VERSION ""

NS_ :

BS_:

BU_:
	NEO
	MCU
	GTW
	EPAS
	DI
	ESP
	SBW
	STW
	APP
	DAS
	XXX

VAL_TABLE_ StW_AnglHP_Spd 16383 "SNA" ;
VAL_TABLE_ DI_aebFaultReason 15 "DI_AEB_FAULT_DAS_REQ_DI_UNAVAIL" 14 "DI_AEB_FAULT_ACCEL_REQ_INVALID" 13 "DI_AEB_FAULT_MIN_TIME_BTWN_EVENTS" 12 "DI_AEB_FAULT_ESP_MIA" 11 "DI_AEB_FAULT_ESP_FAULT" 10 "DI_AEB_FAULT_EPB_NOT_PARKED" 9 "DI_AEB_FAULT_ACCEL_OUT_OF_BOUNDS" 8 "DI_AEB_FAULT_PM_REQUEST" 7 "DI_AEB_FAULT_VEL_EST_ABNORMAL" 6 "DI_AEB_FAULT_DAS_SNA" 5 "DI_AEB_FAULT_DAS_CONTROL_MIA" 4 "DI_AEB_FAULT_SPEED_DELTA" 3 "DI_AEB_FAULT_EBR_FAULT" 2 "DI_AEB_FAULT_PM_MIA" 1 "DI_AEB_FAULT_EPB_MIA" 0 "DI_AEB_FAULT_NONE" ;
VAL_TABLE_ DI_aebLockState 3 "AEB_LOCK_STATE_SNA" 2 "AEB_LOCK_STATE_UNUSED" 1 "AEB_LOCK_STATE_UNLOCKED" 0 "AEB_LOCK_STATE_LOCKED" ;
VAL_TABLE_ DI_aebSmState 7 "DI_AEB_STATE_FAULT" 6 "DI_AEB_STATE_EXIT" 5 "DI_AEB_STATE_STANDSTILL" 4 "DI_AEB_STATE_STOPPING" 3 "DI_AEB_STATE_ENABLE" 2 "DI_AEB_STATE_ENABLE_INIT" 1 "DI_AEB_STATE_STANDBY" 0 "DI_AEB_STATE_UNAVAILABLE" ;
VAL_TABLE_ DI_aebState 7 "AEB_CAN_STATE_SNA" 4 "AEB_CAN_STATE_FAULT" 3 "AEB_CAN_STATE_STANDSTILL" 2 "AEB_CAN_STATE_ENABLED" 1 "AEB_CAN_STATE_STANDBY" 0 "AEB_CAN_STATE_UNAVAILABLE" ;
VAL_TABLE_ DI_epbInterfaceReady 1 "EPB_INTERFACE_READY" 0 "EPB_INTERFACE_NOT_READY" ;
VAL_TABLE_ DI_gear 7 "DI_GEAR_SNA" 4 "DI_GEAR_D" 3 "DI_GEAR_N" 2 "DI_GEAR_R" 1 "DI_GEAR_P" 0 "DI_GEAR_INVALID" ;
VAL_TABLE_ DI_gpoReason 8 "DI_GPO_NUMREASONS" 7 "DI_GPO_CAPACITOR_OVERTEMP" 6 "DI_GPO_NOT_ENOUGH_12V" 5 "DI_GPO_NO_BATTERY_POWER" 4 "DI_GPO_AMBIENT_OVERTEMP" 3 "DI_GPO_FLUID_DELTAT" 2 "DI_GPO_STATOR_OVERTEMP" 1 "DI_GPO_HEATSINK_OVERTEMP" 0 "DI_GPO_OUTLET_OVERTEMP" ;
VAL_TABLE_ DI_immobilizerCondition 1 "DI_IMM_CONDITION_LEARNED" 0 "DI_IMM_CONDITION_VIRGIN_SNA" ;
VAL_TABLE_ DI_immobilizerState 7 "DI_IMM_STATE_FAULT" 6 "DI_IMM_STATE_FAULTRETRY" 5 "DI_IMM_STATE_RESET" 4 "DI_IMM_STATE_LEARN" 3 "DI_IMM_STATE_DISARMED" 2 "DI_IMM_STATE_AUTHENTICATING" 1 "DI_IMM_STATE_REQUEST" 0 "DI_IMM_STATE_INIT_SNA" ;
VAL_TABLE_ DI_limpReason 24 "DI_LIMP_NUMREASONS" 23 "DI_LIMP_CAPACITOR_OVERTEMP" 22 "DI_LIMP_GTW_MIA" 21 "DI_LIMP_TRQCMD_VALIDITY_UNKNOWN" 20 "DI_LIMP_DI_MIA" 19 "DI_LIMP_CONFIG_MISMATCH" 18 "DI_LIMP_HEATSINK_TEMP" 17 "DI_LIMP_PMREQUEST" 16 "DI_LIMP_PMHEARTBEAT" 15 "DI_LIMP_TRQ_CROSS_CHECK" 14 "DI_LIMP_EXTERNAL_COMMAND" 13 "DI_LIMP_WRONG_CS_CALIBRATION" 12 "DI_LIMP_STATOR_TEMP" 11 "DI_LIMP_DELTAT_TOO_NEGATIVE" 10 "DI_LIMP_DELTAT_TOO_POSITIVE" 9 "DI_LIMP_AMBIENT_TEMP" 8 "DI_LIMP_OUTLET_TEMP" 7 "DI_LIMP_LOW_FLOW" 6 "DI_LIMP_BMS_MIA" 5 "DI_LIMP_12V_SUPPLY_UNDERVOLTAGE" 4 "DI_LIMP_NO_FLUID" 3 "DI_LIMP_NO_FUNC_HEATSINK_SENSOR" 2 "DI_LIMP_NO_FUNC_STATORT_SENSOR" 1 "DI_LIMP_BUSV_SENSOR_IRRATIONAL" 0 "DI_LIMP_PHASE_IMBALANCE" ;
VAL_TABLE_ DI_mode 2 "DI_MODE_DYNO" 1 "DI_MODE_DRIVE" 0 "DI_MODE_UNDEF" ;
VAL_TABLE_ DI_motorType 14 "DI_MOTOR_F2AE" 13 "DI_MOTOR_F2AD" 12 "DI_MOTOR_F2AC" 11 "DI_MOTOR_F2AB" 10 "DI_MOTOR_F1AC" 9 "DI_MOTOR_SSR1A" 8 "DI_MOTOR_F1A" 7 "DI_MOTOR_M7M6" 6 "DI_MOTOR_M8A" 5 "DI_MOTOR_M7M5" 4 "DI_MOTOR_M7M4" 3 "DI_MOTOR_M7M3" 2 "DI_MOTOR_ROADSTER_SPORT" 1 "DI_MOTOR_ROADSTER_BASE" 0 "DI_MOTOR_SNA" ;
VAL_TABLE_ DI_speedUnits 1 "DI_SPEED_KPH" 0 "DI_SPEED_MPH" ;
VAL_TABLE_ DI_state 4 "DI_STATE_ENABLE" 3 "DI_STATE_FAULT" 2 "DI_STATE_CLEAR_FAULT" 1 "DI_STATE_STANDBY" 0 "DI_STATE_PREAUTH" ;
VAL_TABLE_ DI_velocityEstimatorState 4 "VE_STATE_BACKUP_MOTOR" 3 "VE_STATE_BACKUP_WHEELS_B" 2 "VE_STATE_BACKUP_WHEELS_A" 1 "VE_STATE_WHEELS_NORMAL" 0 "VE_STATE_NOT_INITIALIZED" ;

BO_ 53 ACCELERATOR: 32 XXX
 SG_ CHECKSUM : 0|16@1+ (1,0) [0|65535] "" XXX
 SG_ COUNTER : 16|8@1+ (1,0) [0|255] "" XXX
 SG_ GEAR : 192|3@1+ (1,0) [0|7] "" XXX
 SG_ ACCELERATOR_PEDAL : 40|8@1+ (1,0) [0|255] "" XXX

BO_ 64 GEAR_ALT: 32 XXX
 SG_ CHECKSUM : 0|16@1+ (1,0) [0|65535] "" XXX
 SG_ COUNTER : 16|8@1+ (1,0) [0|255] "" XXX
 SG_ GEAR : 32|3@1+ (1,0) [0|7] "" XXX

BO_ 69 GEAR: 24 XXX
 SG_ CHECKSUM : 0|16@1+ (1,0) [0|65535] "" XXX
 SG_ COUNTER : 16|8@1+ (1,0) [0|255] "" XXX
 SG_ GEAR : 44|3@1+ (1,0) [0|7] "" XXX

BO_ 80 LKAS: 16 XXX
 SG_ STEER_REQ : 52|1@1+ (1,0) [0|1] "" XXX
 SG_ TORQUE_REQUEST : 41|11@1+ (1,-1024) [0|4095] "" XXX
 SG_ LKA_ICON : 38|2@1+ (1,0) [0|255] "" XXX
 SG_ NEW_SIGNAL_1 : 27|2@1+ (1,0) [0|255] "" XXX
 SG_ LFA_BUTTON : 56|1@1+ (1,0) [0|255] "" XXX
 SG_ COUNTER : 16|8@1+ (1,0) [0|255] "" XXX
 SG_ CHECKSUM : 0|16@1+ (1,0) [0|65535] "" XXX
 SG_ STEER_MODE : 65|3@1+ (1,0) [0|1] "" XXX
 SG_ LKA_WARNING : 32|1@1+ (1,0) [0|1] "" XXX
 SG_ LKA_ASSIST : 62|1@1+ (1,0) [0|1] "" XXX
 SG_ LKA_MODE : 24|3@1+ (1,0) [0|7] "" XXX
 SG_ NEW_SIGNAL_2 : 70|2@0+ (1,0) [0|3] "" XXX
 SG_ HAS_LANE_SAFETY : 80|1@0+ (1,0) [0|1] "" XXX
 SG_ NEW_SIGNAL_3 : 111|8@0+ (1,0) [0|255] "" XXX
 SG_ FCA_SYSWARN : 40|1@0+ (1,0) [0|1] "" XXX

BO_ 81 ADRV_0x51: 32 ADRV
 SG_ COUNTER : 16|8@1+ (1,0) [0|255] "" XXX
 SG_ CHECKSUM : 0|16@1+ (1,0) [0|65535] "" XXX

BO_ 96 ESP_STATUS: 32 XXX
 SG_ CHECKSUM : 0|16@1+ (1,0) [0|65535] "" XXX
 SG_ COUNTER : 16|8@1+ (1,0) [0|255] "" XXX
 SG_ TRACTION_AND_STABILITY_CONTROL : 42|3@1+ (1,0) [0|63] "" XXX
 SG_ BRAKE_PRESSURE : 128|10@1+ (1,0) [0|65535] "" XXX
 SG_ BRAKE_PRESSED : 148|1@1+ (1,0) [0|3] "" XXX

BO_ 101 BRAKE: 32 XXX
 SG_ CHECKSUM : 0|16@1+ (1,0) [0|65535] "" XXX
 SG_ COUNTER : 16|8@1+ (1,0) [0|255] "" XXX
 SG_ BRAKE_POSITION : 40|16@1- (1,0) [0|65535] "" XXX
 SG_ BRAKE_PRESSED : 57|1@1+ (1,0) [0|3] "" XXX

BO_ 112 GEAR_ALT_2: 32 XXX
 SG_ CHECKSUM : 0|16@1+ (1,0) [0|65535] "" XXX
 SG_ COUNTER : 16|8@1+ (1,0) [0|255] "" XXX
 SG_ GEAR : 60|3@1+ (1,0) [0|7] "" XXX

BO_ 160 WHEEL_SPEEDS: 24 XXX
 SG_ CHECKSUM : 0|16@1+ (1,0) [0|65535] "" XXX
 SG_ COUNTER : 16|8@1+ (1,0) [0|255] "" XXX
 SG_ MOVING_FORWARD : 56|1@0+ (1,0) [0|1] "" XXX
 SG_ MOVING_BACKWARD : 57|1@0+ (1,0) [0|1] "" XXX
 SG_ MOVING_FORWARD2 : 58|1@0+ (1,0) [0|1] "" XXX
 SG_ MOVING_BACKWARD2 : 59|1@0+ (1,0) [0|1] "" XXX
 SG_ WHEEL_SPEED_1 : 64|16@1+ (0.03125,0) [0|65535] "kph" XXX
 SG_ WHEEL_SPEED_2 : 80|16@1+ (0.03125,0) [0|65535] "kph" XXX
 SG_ WHEEL_SPEED_3 : 96|16@1+ (0.03125,0) [0|65535] "kph" XXX
 SG_ WHEEL_SPEED_4 : 112|16@1+ (0.03125,0) [0|65535] "kph" XXX

BO_ 234 MDPS: 24 XXX
 SG_ CHECKSUM : 0|16@1+ (1,0) [0|65535] "" XXX
 SG_ COUNTER : 16|8@1+ (1,0) [0|255] "" XXX
 SG_ LKA_ACTIVE : 48|1@0+ (1,0) [0|16777215] "" XXX
 SG_ LKA_FAULT : 54|1@0+ (1,0) [0|1] "" XXX
 SG_ STEERING_OUT_TORQUE : 64|12@1+ (0.1,-204.8) [0|65535] "" XXX
 SG_ STEERING_COL_TORQUE : 80|13@1+ (1,-4095) [0|4095] "" XXX
 SG_ STEERING_ANGLE : 96|16@1- (-0.1,0) [0|255] "deg" XXX
 SG_ STEERING_ANGLE_2 : 128|16@1- (-0.1,0) [0|65535] "deg" XXX

BO_ 256 ACCELERATOR_BRAKE_ALT: 32 XXX
 SG_ CHECKSUM : 0|16@1+ (1,0) [0|65535] "" XXX
 SG_ COUNTER : 16|8@1+ (1,0) [0|255] "" XXX
 SG_ BRAKE_PRESSED : 32|1@1+ (1,0) [0|1] "" XXX
 SG_ ACCELERATOR_PEDAL_PRESSED : 176|1@1+ (1,0) [0|1] "" XXX

BO_ 261 ACCELERATOR_ALT: 32 XXX
 SG_ CHECKSUM : 0|16@1+ (1,0) [0|65535] "" XXX
 SG_ COUNTER : 16|8@1+ (1,0) [0|255] "" XXX
 SG_ ACCELERATOR_PEDAL : 103|10@1+ (0.25,0) [0|1022] "" XXX

BO_ 272 LKAS_ALT: 32 XXX
 SG_ STEER_REQ : 52|1@1+ (1,0) [0|1] "" XXX
 SG_ TORQUE_REQUEST : 41|11@1+ (1,-1024) [0|4095] "" XXX
 SG_ LKA_ICON : 38|2@1+ (1,0) [0|255] "" XXX
 SG_ NEW_SIGNAL_1 : 27|2@1+ (1,0) [0|255] "" XXX
 SG_ LFA_BUTTON : 56|1@1+ (1,0) [0|255] "" XXX
 SG_ COUNTER : 16|8@1+ (1,0) [0|255] "" XXX
 SG_ CHECKSUM : 0|16@1+ (1,0) [0|65535] "" XXX
 SG_ STEER_MODE : 65|3@1+ (1,0) [0|1] "" XXX
 SG_ LKA_WARNING : 32|1@1+ (1,0) [0|1] "" XXX
 SG_ LKA_ASSIST : 62|1@1+ (1,0) [0|1] "" XXX
 SG_ LKA_MODE : 24|3@1+ (1,0) [0|7] "" XXX
 SG_ NEW_SIGNAL_2 : 70|2@0+ (1,0) [0|3] "" XXX
 SG_ HAS_LANE_SAFETY : 80|1@0+ (1,0) [0|1] "" XXX
 SG_ NEW_SIGNAL_3 : 111|8@0+ (1,0) [0|255] "" XXX
 SG_ FCA_SYSWARN : 40|1@0+ (1,0) [0|1] "" XXX

BO_ 293 STEERING_SENSORS: 16 XXX
 SG_ CHECKSUM : 0|16@1+ (1,0) [0|65535] "" XXX
 SG_ COUNTER : 16|8@1+ (1,0) [0|255] "" XXX
 SG_ STEERING_RATE : 40|8@1+ (4,0) [0|1016] "deg/s" XXX
 SG_ STEERING_ANGLE : 24|16@1- (-0.1,0) [0|255] "deg" XXX

BO_ 298 LFA: 16 ADRV
 SG_ STEER_REQ : 52|1@1+ (1,0) [0|1] "" XXX
 SG_ TORQUE_REQUEST : 41|11@1+ (1,-1024) [0|4095] "" XXX
 SG_ LKA_ICON : 38|2@1+ (1,0) [0|255] "" XXX
 SG_ NEW_SIGNAL_1 : 27|2@1+ (1,0) [0|255] "" XXX
 SG_ LFA_BUTTON : 56|1@1+ (1,0) [0|255] "" XXX
 SG_ COUNTER : 16|8@1+ (1,0) [0|255] "" XXX
 SG_ CHECKSUM : 0|16@1+ (1,0) [0|65535] "" XXX
 SG_ STEER_MODE : 65|3@1+ (1,0) [0|1] "" XXX
 SG_ LKA_WARNING : 32|1@1+ (1,0) [0|1] "" XXX
 SG_ LKA_ASSIST : 62|1@1+ (1,0) [0|1] "" XXX
 SG_ LKA_MODE : 24|3@1+ (1,0) [0|7] "" XXX
 SG_ NEW_SIGNAL_2 : 70|2@0+ (1,0) [0|3] "" XXX
 SG_ HAS_LANE_SAFETY : 80|1@0+ (1,0) [0|1] "" XXX
 SG_ NEW_SIGNAL_3 : 111|8@0+ (1,0) [0|255] "" XXX

BO_ 304 GEAR_SHIFTER: 16 XXX
 SG_ CHECKSUM : 0|16@1+ (1,0) [0|65535] "" XXX
 SG_ COUNTER : 16|8@1+ (1,0) [0|255] "" XXX
 SG_ PARK_BUTTON : 32|2@1+ (1,0) [0|3] "" XXX
 SG_ GEAR : 64|3@1+ (1,0) [0|7] "" XXX
 SG_ KNOB_POSITION : 40|3@1+ (1,0) [0|3] "" XXX

BO_ 357 SPAS1: 24 APRK
 SG_ CHECKSUM : 0|16@1+ (1,0) [0|65535] "" XXX
 SG_ COUNTER : 16|8@1+ (1,0) [0|0] "" XXX
 SG_ NEW_SIGNAL_1 : 96|16@1- (0.1,0) [0|0] "" XXX
 SG_ NEW_SIGNAL_2 : 90|3@1+ (1,0) [0|0] "" XXX

BO_ 362 SPAS2: 32 APRK
 SG_ CHECKSUM : 0|16@1+ (1,0) [0|65535] "" XXX
 SG_ COUNTER : 16|8@1+ (1,0) [0|0] "" XXX
 SG_ BLINKER_CONTROL : 133|3@1+ (1,0) [0|0] "" XXX

BO_ 373 TCS: 24 XXX
 SG_ CHECKSUM : 0|16@1+ (1,0) [0|65535] "" XXX
 SG_ COUNTER : 16|8@1+ (1,0) [0|255] "" XXX
 SG_ NEW_SIGNAL_1 : 80|1@0+ (1,0) [0|1] "" XXX
 SG_ NEW_SIGNAL_2 : 74|1@0+ (1,0) [0|1] "" XXX
 SG_ NEW_SIGNAL_3 : 76|1@0+ (1,0) [0|1] "" XXX
 SG_ NEW_SIGNAL_4 : 24|7@1+ (1,0) [0|127] "" XXX
 SG_ aBasis : 32|11@1+ (0.01,-10.23) [0|7] "m/s^2" XXX
 SG_ NEW_SIGNAL_5 : 72|1@0+ (1,0) [0|1] "" XXX
 SG_ NEW_SIGNAL_6 : 128|4@1+ (1,0) [0|15] "" XXX
 SG_ NEW_SIGNAL_7 : 135|2@0+ (1,0) [0|3] "" XXX
 SG_ PROBABLY_EQUIP : 136|2@1+ (1,0) [0|3] "" XXX
 SG_ AEB_EQUIP_MAYBE : 96|1@0+ (1,0) [0|1] "" XXX
 SG_ EQUIP_MAYBE : 64|1@0+ (1,0) [0|1] "" XXX
 SG_ DriverBraking : 81|1@0+ (1,0) [0|1] "" XXX
 SG_ DriverBrakingLowSens : 84|1@1+ (1,0) [0|1] "" XXX
 SG_ ACC_REQ : 68|1@0+ (1,0) [0|1] "" XXX
 SG_ ACCEL_REF_ACC : 48|11@1- (1,0) [0|1023] "" XXX
 SG_ ACCEnable : 67|2@0+ (1,0) [0|3] "" XXX

BO_ 352 ADRV_0x160: 16 ADRV
 SG_ CHECKSUM : 0|16@1+ (1,0) [0|65535] "" XXX
 SG_ COUNTER : 16|8@1+ (1,0) [0|255] "" XXX
 SG_ SET_ME_FF : 64|8@1+ (1,0) [0|255] "" XXX
 SG_ SET_ME_FC : 72|8@1+ (1,0) [0|255] "" XXX
 SG_ SET_ME_2 : 56|8@1+ (1,0) [0|1] "" XXX
 SG_ AEB_SETTING : 24|2@1+ (1,0) [0|255] "" XXX
 SG_ SET_ME_9 : 80|8@1+ (1,0) [0|255] "" XXX

BO_ 384 CAM_0x180: 32 CAMERA
 SG_ CHECKSUM : 0|16@1+ (1,0) [0|65535] "" XXX
 SG_ COUNTER : 16|8@1+ (1,0) [0|255] "" XXX

BO_ 385 CAM_0x181: 32 CAMERA
 SG_ CHECKSUM : 0|16@1+ (1,0) [0|65535] "" XXX
 SG_ COUNTER : 16|8@1+ (1,0) [0|255] "" XXX

BO_ 386 CAM_0x182: 32 CAMERA
 SG_ CHECKSUM : 0|16@1+ (1,0) [0|65535] "" XXX
 SG_ COUNTER : 16|8@1+ (1,0) [0|255] "" XXX

BO_ 387 CAM_0x183: 32 CAMERA
 SG_ CHECKSUM : 0|16@1+ (1,0) [0|65535] "" XXX
 SG_ COUNTER : 16|8@1+ (1,0) [0|255] "" XXX

BO_ 388 CAM_0x184: 32 CAMERA
 SG_ CHECKSUM : 0|16@1+ (1,0) [0|65535] "" XXX
 SG_ COUNTER : 16|8@1+ (1,0) [0|255] "" XXX

BO_ 389 CAM_0x185: 8 CAMERA
 SG_ CHECKSUM : 0|16@1+ (1,0) [0|65535] "" XXX
 SG_ COUNTER : 16|8@1+ (1,0) [0|255] "" XXX

BO_ 416 SCC_CONTROL: 32 ADRV
 SG_ CHECKSUM : 0|16@1+ (1,0) [0|65535] "" XXX
 SG_ NEW_SIGNAL_1 : 64|2@1+ (1,0) [0|3] "" XXX
 SG_ NEW_SIGNAL_8 : 170|4@1+ (1,0) [0|15] "" XXX
 SG_ ZEROS : 215|48@0+ (1,0) [0|281474976710655] "" XXX
 SG_ ZEROS_3 : 191|7@0+ (1,0) [0|127] "" XXX
 SG_ ZEROS_4 : 183|4@0+ (1,0) [0|63] "" XXX
 SG_ ZEROS_6 : 119|16@0+ (1,0) [0|65535] "" XXX
 SG_ ZEROS_8 : 95|5@0+ (1,0) [0|31] "" XXX
 SG_ NEW_SIGNAL_3 : 109|2@0+ (1,0) [0|1] "" XXX
 SG_ SET_ME_TMP_64 : 55|8@0+ (1,0) [0|63] "" XXX
 SG_ SET_ME_2 : 105|3@1+ (1,0) [0|7] "" XXX
 SG_ NEW_SIGNAL_6 : 104|1@0+ (1,0) [0|1] "" XXX
 SG_ COUNTER : 16|8@1+ (1,0) [0|255] "" XXX
 SG_ ZEROS_9 : 71|5@1+ (1,0) [0|15] "" XXX
 SG_ ZEROS_10 : 111|2@0+ (1,0) [0|3] "" XXX
 SG_ SET_ME_3 : 45|2@0+ (1,0) [0|3] "" XXX
 SG_ ObjValid : 46|1@0+ (1,0) [0|3] "" XXX
 SG_ NEW_SIGNAL_2 : 168|2@1+ (1,0) [0|3] "" XXX
 SG_ OBJ_STATUS : 176|3@1+ (1,0) [0|7] "" XXX
 SG_ ACC_ObjDist : 24|11@1+ (0.1,0) [0|204.7] "m" XXX
 SG_ ZEROS_5 : 77|11@1+ (1,0) [0|2047] "" XXX
 SG_ DISTANCE_SETTING : 88|3@1+ (1,0) [0|3] "" XXX
 SG_ ZEROS_2 : 207|5@0+ (1,0) [0|63] "" XXX
 SG_ CRUISE_STANDSTILL : 76|1@1+ (1,0) [0|1] "" XXX
 SG_ aReqRaw : 140|11@1+ (0.01,-10.23) [-10.23|10.24] "m/s^2" XXX
 SG_ aReqValue : 128|11@1+ (0.01,-10.23) [-10.23|10.24] "m/s^2" XXX
 SG_ ZEROS_7 : 63|8@0+ (1,0) [0|255] "" XXX
 SG_ ACCMode : 68|3@1+ (1,0) [0|7] "" XXX
 SG_ NEW_SIGNAL_12 : 35|9@1+ (0.1,0) [0|255] "" XXX
 SG_ JerkLowerLimit : 166|7@0+ (0.1,0) [0|12.7] "m/s^3" XXX
 SG_ StopReq : 184|1@0+ (1,0) [0|1] "" XXX
 SG_ NEW_SIGNAL_15 : 192|11@1+ (0.1,0) [0|204.7] "m" XXX
 SG_ VSetDis : 103|8@0+ (1,0) [0|255] "km/h or mph" XXX
 SG_ MainMode_ACC : 66|1@1+ (1,0) [0|1] "" XXX
 SG_ JerkUpperLimit : 158|7@0+ (0.1,0) [0|0] "" XXX

BO_ 426 CRUISE_BUTTONS_ALT: 16 XXX
 SG_ CHECKSUM : 0|16@1+ (1,0) [0|65535] "" XXX
 SG_ COUNTER : 16|8@1+ (1,0) [0|255] "" XXX
 SG_ NEW_SIGNAL_1 : 24|4@1+ (1,0) [0|15] "" XXX
 SG_ SET_ME_1 : 28|2@1+ (1,0) [0|3] "" XXX
 SG_ DISTANCE_UNIT : 30|1@1+ (1,0) [0|1] "" XXX
 SG_ NEW_SIGNAL_2 : 31|3@1+ (1,0) [0|7] "" XXX
 SG_ ADAPTIVE_CRUISE_MAIN_BTN : 34|1@1+ (1,0) [0|1] "" XXX
 SG_ NEW_SIGNAL_3 : 35|1@1+ (1,0) [0|1] "" XXX
 SG_ LFA_BTN : 39|1@1+ (1,0) [0|1] "" XXX
 SG_ CRUISE_BUTTONS : 36|3@1+ (1,0) [0|4] "" XXX
 SG_ NEW_SIGNAL_4 : 40|1@1+ (1,0) [0|1] "" XXX
 SG_ NORMAL_CRUISE_MAIN_BTN : 41|1@1+ (1,0) [0|1] "" XXX
 SG_ NEW_SIGNAL_5 : 42|2@1+ (1,0) [0|3] "" XXX
 SG_ SET_ME_2 : 44|3@1+ (1,0) [0|7] "" XXX
 SG_ NEW_SIGNAL_6 : 47|1@1+ (1,0) [0|1] "" XXX
 SG_ BYTE6 : 48|8@1+ (1,0) [0|255] "" XXX
 SG_ BYTE7 : 56|8@1+ (1,0) [0|255] "" XXX
 SG_ BYTE8 : 64|8@1+ (1,0) [0|255] "" XXX
 SG_ BYTE9 : 72|8@1+ (1,0) [0|255] "" XXX
 SG_ BYTE10 : 80|8@1+ (1,0) [0|255] "" XXX
 SG_ BYTE11 : 88|8@1+ (1,0) [0|255] "" XXX
 SG_ BYTE12 : 96|8@1+ (1,0) [0|255] "" XXX
 SG_ BYTE13 : 104|8@1+ (1,0) [0|255] "" XXX
 SG_ BYTE14 : 112|8@1+ (1,0) [0|255] "" XXX
 SG_ BYTE15 : 120|8@1+ (1,0) [0|255] "" XXX

BO_ 438 CAM_0x1b6: 32 CAMERA
 SG_ CHECKSUM : 0|16@1+ (1,0) [0|65535] "" XXX
 SG_ COUNTER : 16|8@1+ (1,0) [0|255] "" XXX

BO_ 439 CAM_0x1b7: 32 CAMERA
 SG_ CHECKSUM : 0|16@1+ (1,0) [0|65535] "" XXX
 SG_ COUNTER : 16|8@1+ (1,0) [0|255] "" XXX

BO_ 440 CAM_0x1b8: 32 CAMERA
 SG_ CHECKSUM : 0|16@1+ (1,0) [0|65535] "" XXX
 SG_ COUNTER : 16|8@1+ (1,0) [0|255] "" XXX

BO_ 441 CAM_0x1b9: 32 CAMERA
 SG_ CHECKSUM : 0|16@1+ (1,0) [0|65535] "" XXX
 SG_ COUNTER : 16|8@1+ (1,0) [0|255] "" XXX

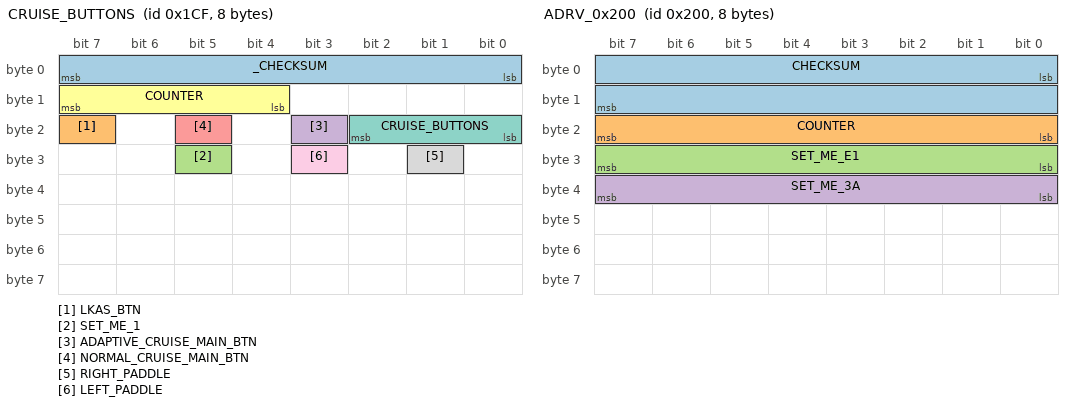
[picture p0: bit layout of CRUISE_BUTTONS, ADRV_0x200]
BO_ 463 CRUISE_BUTTONS: 8 XXX
 SG_ _CHECKSUM : 0|8@1+ (1,0) [0|65535] "" XXX
 SG_ LKAS_BTN : 23|1@1+ (1,0) [0|1] "" XXX
 SG_ SET_ME_1 : 29|1@1+ (1,0) [0|1] "" XXX
 SG_ ADAPTIVE_CRUISE_MAIN_BTN : 19|1@1+ (1,0) [0|1] "" XXX
 SG_ NORMAL_CRUISE_MAIN_BTN : 21|1@1+ (1,0) [0|1] "" XXX
 SG_ COUNTER : 12|4@1+ (1,0) [0|255] "" XXX
 SG_ CRUISE_BUTTONS : 16|3@1+ (1,0) [0|3] "" XXX
 SG_ RIGHT_PADDLE : 25|1@1+ (1,0) [0|1] "" XXX
 SG_ LEFT_PADDLE : 27|1@1+ (1,0) [0|1] "" XXX

BO_ 474 ADRV_0x1da: 32 ADRV
 SG_ CHECKSUM : 0|16@1+ (1,0) [0|65535] "" XXX
 SG_ COUNTER : 16|8@1+ (1,0) [0|255] "" XXX
 SG_ SET_ME_22 : 31|8@0+ (1,0) [0|255] "" XXX
 SG_ SET_ME_41 : 47|8@0+ (1,0) [0|255] "" XXX

BO_ 480 LFAHDA_CLUSTER: 16 ADRV
 SG_ CHECKSUM : 0|16@1+ (1,0) [0|65535] "" XXX
 SG_ COUNTER : 16|8@1+ (1,0) [0|255] "" XXX
 SG_ HDA_ICON : 31|1@1+ (1,0) [0|1] "" XXX
 SG_ LFA_ICON : 47|2@1+ (1,0) [0|3] "" XXX
 SG_ NEW_SIGNAL_1 : 32|3@1+ (1,0) [0|7] "" XXX
 SG_ NEW_SIGNAL_2 : 30|1@0+ (1,0) [0|1] "" XXX
 SG_ NEW_SIGNAL_3 : 49|1@0+ (1,0) [0|1] "" XXX
 SG_ NEW_SIGNAL_4 : 24|1@0+ (1,0) [0|1] "" XXX

BO_ 490 ADRV_0x1ea: 32 ADRV
 SG_ CHECKSUM : 0|16@1+ (1,0) [0|65535] "" XXX
 SG_ COUNTER : 16|8@1+ (1,0) [0|255] "" XXX
 SG_ SET_ME_1C : 31|8@0+ (1,0) [0|255] "" XXX
 SG_ NEW_SIGNAL_1 : 32|2@1+ (1,0) [0|3] "" XXX
 SG_ NEW_SIGNAL_2 : 47|2@0+ (1,0) [0|3] "" XXX
 SG_ NEW_SIGNAL_3 : 55|8@0+ (1,0) [0|255] "" XXX
 SG_ NEW_SIGNAL_4 : 64|6@1+ (1,0) [0|31] "" XXX
 SG_ NEW_SIGNAL_5 : 72|2@1+ (1,0) [0|3] "" XXX
 SG_ NEW_SIGNAL_6 : 75|5@1+ (1,0) [0|31] "" XXX
 SG_ NEW_SIGNAL_7 : 80|5@1+ (1,0) [0|31] "" XXX
 SG_ NEW_SIGNAL_8 : 88|7@1+ (1,0) [0|127] "" XXX
 SG_ NEW_SIGNAL_9 : 96|1@0+ (1,0) [0|1] "" XXX
 SG_ NEW_SIGNAL_10 : 143|5@0+ (1,0) [0|31] "" XXX
 SG_ NEW_SIGNAL_11 : 144|3@1+ (1,0) [0|7] "" XXX
 SG_ NEW_SIGNAL_12 : 152|6@1+ (1,0) [0|63] "" XXX
 SG_ NEW_SIGNAL_13 : 160|1@0+ (1,0) [0|1] "" XXX
 SG_ NEW_SIGNAL_14 : 163|5@1+ (1,0) [0|31] "" XXX
 SG_ NEW_SIGNAL_15 : 175|4@0+ (1,0) [0|63] "" XXX
 SG_ NEW_SIGNAL_16 : 168|3@1+ (1,0) [0|7] "" XXX
 SG_ NEW_SIGNAL_17 : 176|2@1+ (1,0) [0|3] "" XXX
 SG_ NEW_SIGNAL_18 : 184|1@0+ (1,0) [0|1] "" XXX
 SG_ NEW_SIGNAL_19 : 208|3@1+ (1,0) [0|7] "" XXX
 SG_ NEW_SIGNAL_20 : 212|1@0+ (1,0) [0|1] "" XXX
 SG_ SET_ME_FF : 120|8@1+ (1,0) [0|255] "" XXX
 SG_ SET_ME_TMP_F : 232|5@1+ (1,0) [0|31] "" XXX
 SG_ SET_ME_TMP_F_2 : 240|5@1+ (1,0) [0|31] "" XXX

BO_ 507 CAM_0x1fb: 32 CAMERA
 SG_ CHECKSUM : 0|16@1+ (1,0) [0|65535] "" XXX
 SG_ COUNTER : 16|8@1+ (1,0) [0|255] "" XXX

BO_ 512 ADRV_0x200: 8 ADRV
 SG_ CHECKSUM : 0|16@1+ (1,0) [0|65535] "" XXX
 SG_ COUNTER : 16|8@1+ (1,0) [0|255] "" XXX
 SG_ SET_ME_E1 : 24|8@1+ (1,0) [0|255] "" XXX
 SG_ SET_ME_3A : 32|8@1+ (1,0) [0|255] "" XXX

BO_ 513 RADAR_0x201: 32 FRONT_RADAR
 SG_ CHECKSUM : 0|16@1+ (1,0) [0|65535] "" XXX
 SG_ COUNTER : 16|8@1+ (1,0) [0|255] "" XXX

BO_ 528 RADAR_0x210: 32 FRONT_RADAR
 SG_ CHECKSUM : 0|16@1+ (1,0) [0|65535] "" XXX
 SG_ COUNTER : 16|8@1+ (1,0) [0|255] "" XXX

BO_ 529 RADAR_0x211: 32 FRONT_RADAR
 SG_ CHECKSUM : 0|16@1+ (1,0) [0|65535] "" XXX
 SG_ COUNTER : 16|8@1+ (1,0) [0|255] "" XXX

BO_ 530 RADAR_0x212: 32 FRONT_RADAR
 SG_ CHECKSUM : 0|16@1+ (1,0) [0|65535] "" XXX
 SG_ COUNTER : 16|8@1+ (1,0) [0|255] "" XXX

BO_ 531 RADAR_0x213: 32 FRONT_RADAR
 SG_ CHECKSUM : 0|16@1+ (1,0) [0|65535] "" XXX
 SG_ COUNTER : 16|8@1+ (1,0) [0|255] "" XXX

BO_ 532 RADAR_0x214: 32 FRONT_RADAR
 SG_ CHECKSUM : 0|16@1+ (1,0) [0|65535] "" XXX
 SG_ COUNTER : 16|8@1+ (1,0) [0|255] "" XXX

BO_ 533 RADAR_0x215: 32 FRONT_RADAR
 SG_ CHECKSUM : 0|16@1+ (1,0) [0|65535] "" XXX
 SG_ COUNTER : 16|8@1+ (1,0) [0|255] "" XXX

BO_ 534 RADAR_0x216: 32 FRONT_RADAR
 SG_ CHECKSUM : 0|16@1+ (1,0) [0|65535] "" XXX
 SG_ COUNTER : 16|8@1+ (1,0) [0|255] "" XXX

BO_ 535 RADAR_0x217: 32 FRONT_RADAR
 SG_ CHECKSUM : 0|16@1+ (1,0) [0|65535] "" XXX
 SG_ COUNTER : 16|8@1+ (1,0) [0|255] "" XXX

BO_ 536 RADAR_0x218: 32 FRONT_RADAR
 SG_ CHECKSUM : 0|16@1+ (1,0) [0|65535] "" XXX
 SG_ COUNTER : 16|8@1+ (1,0) [0|255] "" XXX

BO_ 537 RADAR_0x219: 32 FRONT_RADAR
 SG_ CHECKSUM : 0|16@1+ (1,0) [0|65535] "" XXX
 SG_ COUNTER : 16|8@1+ (1,0) [0|255] "" XXX

BO_ 538 RADAR_0x21a: 32 FRONT_RADAR
 SG_ CHECKSUM : 0|16@1+ (1,0) [0|65535] "" XXX
 SG_ COUNTER : 16|8@1+ (1,0) [0|255] "" XXX

BO_ 539 RADAR_0x21b: 32 FRONT_RADAR
 SG_ CHECKSUM : 0|16@1+ (1,0) [0|65535] "" XXX
 SG_ COUNTER : 16|8@1+ (1,0) [0|255] "" XXX

BO_ 540 RADAR_0x21c: 32 FRONT_RADAR
 SG_ CHECKSUM : 0|16@1+ (1,0) [0|65535] "" XXX
 SG_ COUNTER : 16|8@1+ (1,0) [0|255] "" XXX

BO_ 541 RADAR_0x21d: 32 FRONT_RADAR
 SG_ CHECKSUM : 0|16@1+ (1,0) [0|65535] "" XXX
 SG_ COUNTER : 16|8@1+ (1,0) [0|255] "" XXX

BO_ 542 RADAR_0x21e: 32 FRONT_RADAR
 SG_ CHECKSUM : 0|16@1+ (1,0) [0|65535] "" XXX
 SG_ COUNTER : 16|8@1+ (1,0) [0|255] "" XXX

BO_ 543 RADAR_0x21f: 32 FRONT_RADAR
 SG_ CHECKSUM : 0|16@1+ (1,0) [0|65535] "" XXX
 SG_ COUNTER : 16|8@1+ (1,0) [0|255] "" XXX

BO_ 576 RADAR_0x240: 16 FRONT_RADAR
 SG_ CHECKSUM : 0|16@1+ (1,0) [0|65535] "" XXX
 SG_ COUNTER : 16|8@1+ (1,0) [0|255] "" XXX

BO_ 593 RADAR_0x251: 16 FRONT_RADAR
 SG_ CHECKSUM : 0|16@1+ (1,0) [0|65535] "" XXX
 SG_ COUNTER : 16|8@1+ (1,0) [0|255] "" XXX

BO_ 674 CAM_0x2a2: 32 CAMERA
 SG_ CHECKSUM : 0|16@1+ (1,0) [0|65535] "" XXX
 SG_ COUNTER : 16|8@1+ (1,0) [0|255] "" XXX

BO_ 675 CAM_0x2a3: 32 CAMERA
 SG_ CHECKSUM : 0|16@1+ (1,0) [0|65535] "" XXX
 SG_ COUNTER : 16|8@1+ (1,0) [0|255] "" XXX

BO_ 676 CAM_0x2a4: 24 XXX
 SG_ CHECKSUM : 0|16@1+ (1,0) [0|65535] "" XXX
 SG_ COUNTER : 16|8@1+ (1,0) [0|255] "" XXX
 SG_ BYTE3 : 24|8@1+ (1,0) [0|255] "" XXX
 SG_ BYTE4 : 32|8@1+ (1,0) [0|255] "" XXX
 SG_ BYTE5 : 40|8@1+ (1,0) [0|255] "" XXX
 SG_ BYTE6 : 48|8@1+ (1,0) [0|255] "" XXX
 SG_ LEFT_LANE_LINE : 56|2@1+ (1,0) [0|3] "" XXX
 SG_ SET_ME_0 : 58|2@1+ (1,0) [0|3] "" XXX
 SG_ RIGHT_LANE_LINE : 60|2@1+ (1,0) [0|3] "" XXX
 SG_ SET_ME_0_2 : 62|2@1+ (1,0) [0|3] "" XXX
 SG_ BYTE8 : 64|8@1+ (1,0) [0|255] "" XXX
 SG_ BYTE9 : 72|8@1+ (1,0) [0|255] "" XXX
 SG_ BYTE10 : 80|8@1+ (1,0) [0|255] "" XXX
 SG_ BYTE11 : 88|8@1+ (1,0) [0|255] "" XXX
 SG_ BYTE12 : 96|8@1+ (1,0) [0|255] "" XXX
 SG_ BYTE13 : 104|8@1+ (1,0) [0|255] "" XXX
 SG_ BYTE14 : 112|8@1+ (1,0) [0|255] "" XXX
 SG_ BYTE15 : 120|8@1+ (1,0) [0|255] "" XXX
 SG_ BYTE16 : 128|8@1+ (1,0) [0|255] "" XXX
 SG_ BYTE17 : 136|8@1+ (1,0) [0|255] "" XXX
 SG_ BYTE18 : 144|8@1+ (1,0) [0|255] "" XXX
 SG_ BYTE19 : 152|8@1+ (1,0) [0|255] "" XXX
 SG_ BYTE20 : 160|8@1+ (1,0) [0|255] "" XXX
 SG_ BYTE21 : 168|8@1+ (1,0) [0|255] "" XXX
 SG_ BYTE22 : 176|8@1+ (1,0) [0|255] "" XXX
 SG_ BYTE23 : 184|8@1+ (1,0) [0|255] "" XXX

BO_ 699 CAM_0x2bb: 32 CAMERA
 SG_ CHECKSUM : 0|16@1+ (1,0) [0|65535] "" XXX
 SG_ COUNTER : 16|8@1+ (1,0) [0|255] "" XXX

BO_ 700 CAM_0x2bc: 32 CAMERA
 SG_ CHECKSUM : 0|16@1+ (1,0) [0|65535] "" XXX
 SG_ COUNTER : 16|8@1+ (1,0) [0|255] "" XXX

BO_ 701 CAM_0x2bd: 32 CAMERA
 SG_ CHECKSUM : 0|16@1+ (1,0) [0|65535] "" XXX
 SG_ COUNTER : 16|8@1+ (1,0) [0|255] "" XXX

BO_ 702 CAM_0x2be: 32 CAMERA
 SG_ CHECKSUM : 0|16@1+ (1,0) [0|65535] "" XXX
 SG_ COUNTER : 16|8@1+ (1,0) [0|255] "" XXX

BO_ 736 MANUAL_SPEED_LIMIT_ASSIST: 32 XXX
 SG_ CHECKSUM : 0|16@1+ (1,0) [0|65535] "" XXX
 SG_ COUNTER : 16|8@1+ (1,0) [0|255] "" XXX
 SG_ MSLA_STATUS : 26|2@1+ (1,0) [0|3] "" XXX
 SG_ MSLA_ENABLED : 38|1@1+ (1,0) [0|1] "" XXX
 SG_ MAX_SPEED : 55|8@0+ (1,0) [0|255] "" XXX
 SG_ MAX_SPEED_COPY : 144|8@1+ (1,0) [0|255] "" XXX

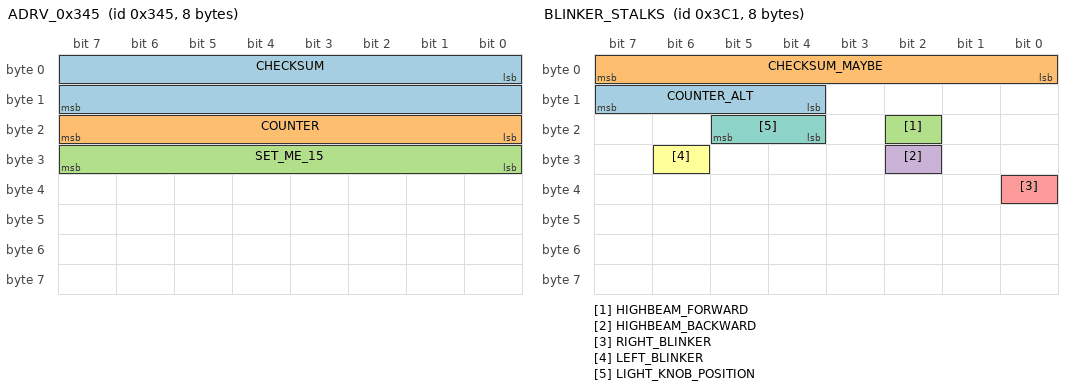
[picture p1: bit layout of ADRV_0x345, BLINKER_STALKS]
BO_ 837 ADRV_0x345: 8 ADRV
 SG_ CHECKSUM : 0|16@1+ (1,0) [0|65535] "" XXX
 SG_ COUNTER : 16|8@1+ (1,0) [0|255] "" XXX
 SG_ SET_ME_15 : 24|8@1+ (1,0) [0|255] "" XXX

BO_ 866 CAM_0x362: 32 CAMERA
 SG_ CHECKSUM : 0|16@1+ (1,0) [0|65535] "" XXX
 SG_ COUNTER : 16|8@1+ (1,0) [0|255] "" XXX
 SG_ BYTE3 : 24|8@1+ (1,0) [0|255] "" XXX
 SG_ BYTE4 : 32|8@1+ (1,0) [0|255] "" XXX
 SG_ BYTE5 : 40|8@1+ (1,0) [0|255] "" XXX
 SG_ BYTE6 : 48|8@1+ (1,0) [0|255] "" XXX
 SG_ LEFT_LANE_LINE : 56|2@1+ (1,0) [0|3] "" XXX
 SG_ SET_ME_0 : 58|2@1+ (1,0) [0|3] "" XXX
 SG_ RIGHT_LANE_LINE : 60|2@1+ (1,0) [0|3] "" XXX
 SG_ SET_ME_0_2 : 62|2@1+ (1,0) [0|3] "" XXX
 SG_ BYTE8 : 64|8@1+ (1,0) [0|255] "" XXX
 SG_ BYTE9 : 72|8@1+ (1,0) [0|255] "" XXX
 SG_ BYTE10 : 80|8@1+ (1,0) [0|255] "" XXX
 SG_ BYTE11 : 88|8@1+ (1,0) [0|255] "" XXX
 SG_ BYTE12 : 96|8@1+ (1,0) [0|255] "" XXX
 SG_ BYTE13 : 104|8@1+ (1,0) [0|255] "" XXX
 SG_ BYTE14 : 112|8@1+ (1,0) [0|255] "" XXX
 SG_ BYTE15 : 120|8@1+ (1,0) [0|255] "" XXX
 SG_ BYTE16 : 128|8@1+ (1,0) [0|255] "" XXX
 SG_ BYTE17 : 136|8@1+ (1,0) [0|255] "" XXX
 SG_ BYTE18 : 144|8@1+ (1,0) [0|255] "" XXX
 SG_ BYTE19 : 152|8@1+ (1,0) [0|255] "" XXX
 SG_ BYTE20 : 160|8@1+ (1,0) [0|255] "" XXX
 SG_ BYTE21 : 168|8@1+ (1,0) [0|255] "" XXX
 SG_ BYTE22 : 176|8@1+ (1,0) [0|255] "" XXX
 SG_ BYTE23 : 184|8@1+ (1,0) [0|255] "" XXX
 SG_ BYTE24 : 192|8@1+ (1,0) [0|255] "" XXX
 SG_ BYTE25 : 200|8@1+ (1,0) [0|255] "" XXX
 SG_ BYTE26 : 208|8@1+ (1,0) [0|255] "" XXX
 SG_ BYTE27 : 216|8@1+ (1,0) [0|255] "" XXX
 SG_ BYTE28 : 224|8@1+ (1,0) [0|255] "" XXX
 SG_ BYTE29 : 232|8@1+ (1,0) [0|255] "" XXX
 SG_ BYTE30 : 240|8@1+ (1,0) [0|255] "" XXX
 SG_ BYTE31 : 248|8@1+ (1,0) [0|255] "" XXX

BO_ 961 BLINKER_STALKS: 8 XXX
 SG_ COUNTER_ALT : 15|4@0+ (1,0) [0|15] "" XXX
 SG_ CHECKSUM_MAYBE : 7|8@0+ (1,0) [0|255] "" XXX
 SG_ HIGHBEAM_FORWARD : 18|1@0+ (1,0) [0|1] "" XXX
 SG_ HIGHBEAM_BACKWARD : 26|1@0+ (1,0) [0|1] "" XXX
 SG_ RIGHT_BLINKER : 32|1@0+ (1,0) [0|1] "" XXX
 SG_ LEFT_BLINKER : 30|1@0+ (1,0) [0|1] "" XXX
 SG_ LIGHT_KNOB_POSITION : 21|2@0+ (1,0) [0|3] "" XXX

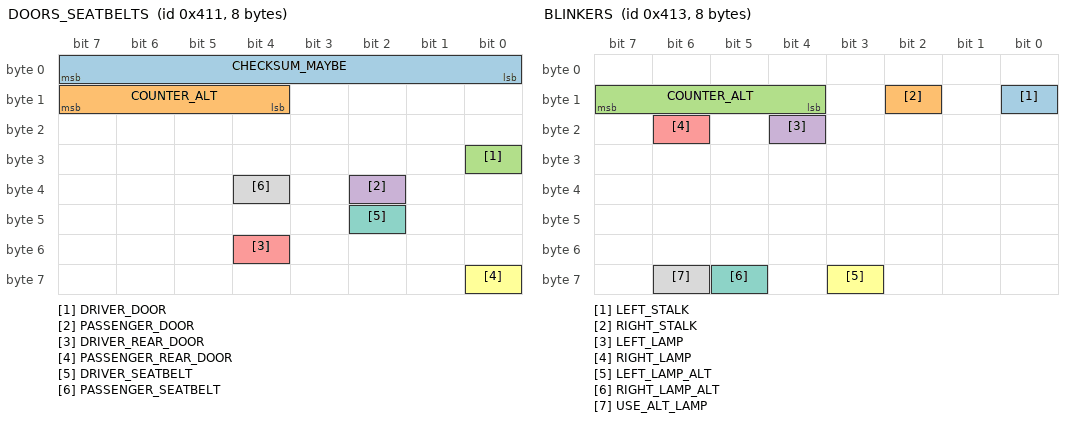
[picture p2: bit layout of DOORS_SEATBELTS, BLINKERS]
BO_ 1041 DOORS_SEATBELTS: 8 XXX
 SG_ CHECKSUM_MAYBE : 7|8@0+ (1,0) [0|65535] "" XXX
 SG_ COUNTER_ALT : 15|4@0+ (1,0) [0|15] "" XXX
 SG_ DRIVER_DOOR : 24|1@1+ (1,0) [0|1] "" XXX
 SG_ PASSENGER_DOOR : 34|1@0+ (1,0) [0|1] "" XXX
 SG_ DRIVER_REAR_DOOR : 52|1@0+ (1,0) [0|1] "" XXX
 SG_ PASSENGER_REAR_DOOR : 56|1@0+ (1,0) [0|1] "" XXX
 SG_ DRIVER_SEATBELT : 42|1@0+ (1,0) [0|1] "" XXX
 SG_ PASSENGER_SEATBELT : 36|1@0+ (1,0) [0|1] "" XXX

BO_ 1043 BLINKERS: 8 XXX
 SG_ LEFT_STALK : 8|1@0+ (1,0) [0|1] "" XXX
 SG_ RIGHT_STALK : 10|1@0+ (1,0) [0|1] "" XXX
 SG_ COUNTER_ALT : 15|4@0+ (1,0) [0|15] "" XXX
 SG_ LEFT_LAMP : 20|1@0+ (1,0) [0|1] "" XXX
 SG_ RIGHT_LAMP : 22|1@0+ (1,0) [0|1] "" XXX
 SG_ LEFT_LAMP_ALT : 59|1@0+ (1,0) [0|1] "" XXX
 SG_ RIGHT_LAMP_ALT : 61|1@0+ (1,0) [0|1] "" XXX
 SG_ USE_ALT_LAMP : 62|1@0+ (1,0) [0|1] "" XXX

BO_ 1240 CLUSTER_INFO: 8 XXX
 SG_ DISTANCE_UNIT : 0|1@1+ (1,0) [0|1] "" XXX

BO_ 442 BLINDSPOTS_REAR_CORNERS: 24 XXX
 SG_ COUNTER : 16|8@1+ (1,0) [0|255] "" XXX
 SG_ CHECKSUM : 0|16@1+ (1,0) [0|65535] "" XXX
 SG_ NEW_SIGNAL_2 : 96|1@0+ (1,0) [0|1] "" XXX
 SG_ COLLISION_AVOIDANCE_ACTIVE : 68|1@0+ (1,0) [0|1] "" XXX
 SG_ LEFT_MB : 30|1@0+ (1,0) [0|3] "" XXX
 SG_ LEFT_BLOCKED : 24|1@0+ (1,0) [0|1] "" XXX
 SG_ MORE_LEFT_PROB : 32|1@1+ (1,0) [0|3] "" XXX
 SG_ FL_INDICATOR : 46|6@0+ (1,0) [0|1] "" XXX
 SG_ FR_INDICATOR : 54|6@0+ (1,0) [0|63] "" XXX
 SG_ RIGHT_BLOCKED : 64|1@0+ (1,0) [0|1] "" XXX

BO_ 874 BLINDSPOTS_FRONT_CORNER_2: 16 XXX
 SG_ COUNTER : 16|8@1+ (1,0) [0|255] "" XXX
 SG_ CHECKSUM : 0|16@1+ (1,0) [0|65535] "" XXX

BO_ 485 BLINDSPOTS_FRONT_CORNER_1: 16 XXX
 SG_ COUNTER : 16|8@1+ (1,0) [0|255] "" XXX
 SG_ CHECKSUM : 0|16@1+ (1,0) [0|65535] "" XXX
 SG_ NEW_SIGNAL_1 : 108|2@0+ (1,0) [0|3] "" XXX
 SG_ NEW_SIGNAL_2 : 96|1@0+ (1,0) [0|1] "" XXX
 SG_ NEW_SIGNAL_3 : 88|1@0+ (1,0) [0|1] "" XXX
 SG_ NEW_SIGNAL_4 : 80|1@0+ (1,0) [0|1] "" XXX
 SG_ NEW_SIGNAL_5 : 31|2@0+ (1,0) [0|3] "" XXX
 SG_ REVERSING : 24|1@0+ (1,0) [0|1] "" XXX
 SG_ NEW_SIGNAL_7 : 32|2@1+ (1,0) [0|3] "" XXX
 SG_ NEW_SIGNAL_8 : 47|8@0+ (1,0) [0|255] "" XXX
 SG_ NEW_SIGNAL_9 : 55|8@0+ (1,0) [0|255] "" XXX

BO_ 506 CLUSTER_SPEED_LIMIT: 32 XXX
 SG_ SPEED_LIMIT_3 : 119|8@0+ (1,0) [0|255] "" XXX
 SG_ SPEED_LIMIT_2 : 47|7@0+ (1,0) [0|255] "" XXX
 SG_ SPEED_LIMIT_1 : 39|7@0+ (1,0) [0|255] "" XXX
 SG_ SPEED_CHANGE_BLINKING : 129|1@1+ (1,0) [0|3] "" XXX
 SG_ CHIME_2 : 122|2@1+ (1,0) [0|7] "" XXX
 SG_ CHIME_1 : 133|1@0+ (1,0) [0|1] "" XXX
 SG_ ARROW_DOWN : 120|1@0+ (1,0) [0|1] "" XXX
 SG_ ARROW_UP : 121|1@0+ (1,0) [0|1] "" XXX
 SG_ SECONDARY_LIMIT_1 : 79|8@0+ (1,0) [0|127] "" XXX
 SG_ SECONDARY_LIMIT_2 : 103|8@0+ (1,0) [0|127] "" XXX
 SG_ SCHOOL_ZONE : 155|1@0+ (1,0) [0|1] "" XXX

BO_ 1144 DRIVE_MODE: 8 XXX
 SG_ DRIVE_MODE : 0|16@1+ (1,-61611) [0|61611] "" XXX
 SG_ DRIVE_MODE2 : 28|3@1+ (1,0) [1|3] "" XXX

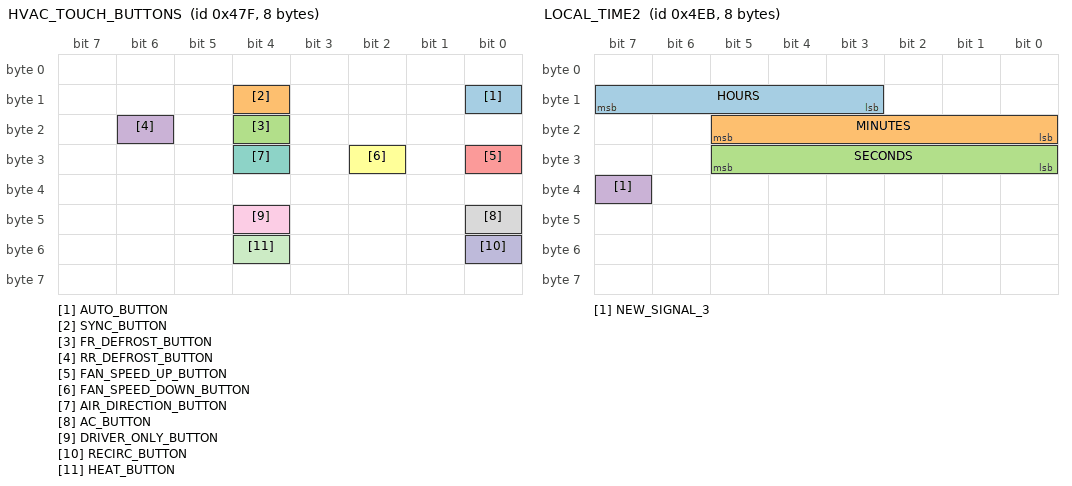
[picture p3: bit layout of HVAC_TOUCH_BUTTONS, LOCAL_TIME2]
BO_ 1151 HVAC_TOUCH_BUTTONS: 8 XXX
 SG_ AUTO_BUTTON : 8|1@0+ (1,0) [0|1] "" XXX
 SG_ SYNC_BUTTON : 12|1@0+ (1,0) [0|1] "" XXX
 SG_ FR_DEFROST_BUTTON : 20|1@0+ (1,0) [0|1] "" XXX
 SG_ RR_DEFROST_BUTTON : 22|1@0+ (1,0) [0|1] "" XXX
 SG_ FAN_SPEED_UP_BUTTON : 24|1@0+ (1,0) [0|1] "" XXX
 SG_ FAN_SPEED_DOWN_BUTTON : 26|1@0+ (1,0) [0|1] "" XXX
 SG_ AIR_DIRECTION_BUTTON : 28|1@0+ (1,0) [0|1] "" XXX
 SG_ AC_BUTTON : 40|1@0+ (1,0) [0|1] "" XXX
 SG_ DRIVER_ONLY_BUTTON : 44|1@0+ (1,0) [0|1] "" XXX
 SG_ RECIRC_BUTTON : 48|1@0+ (1,0) [0|1] "" XXX
 SG_ HEAT_BUTTON : 52|1@0+ (1,0) [0|1] "" XXX

BO_ 1259 LOCAL_TIME2: 8 XXX
 SG_ HOURS : 15|5@0+ (1,0) [0|31] "" XXX
 SG_ MINUTES : 21|6@0+ (1,0) [0|63] "" XXX
 SG_ SECONDS : 24|6@1+ (1,0) [0|63] "" XXX
 SG_ NEW_SIGNAL_3 : 39|1@0+ (1,0) [0|1] "" XXX

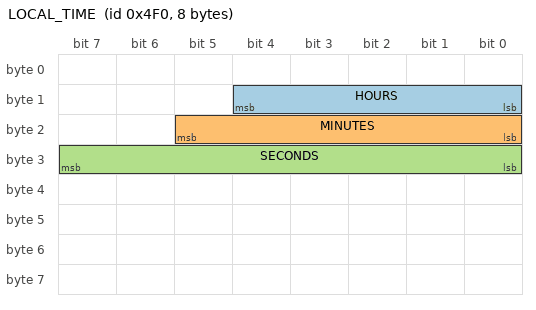
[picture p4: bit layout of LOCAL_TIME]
BO_ 1264 LOCAL_TIME: 8 XXX
 SG_ HOURS : 12|5@0+ (1,0) [0|31] "" XXX
 SG_ MINUTES : 21|6@0+ (1,0) [0|63] "" XXX
 SG_ SECONDS : 31|8@0+ (1,0) [0|59] "" XXX

CM_ "AUTOGENERATED FILE, DO NOT EDIT";

CM_ "Imported file _honda_common.dbc starts here";
CM_ SG_ 304 "Seems to be platform-agnostic";
CM_ SG_ 316 "Should exist on Nidec";
CM_ SG_ 420 BRAKE_HOLD_RELATED "On when Brake Hold engaged";
CM_ SG_ 490 LONG_ACCEL "wheel speed derivative, noisy and zero snapping";
CM_ SG_ 773 PASS_AIRBAG_ON "Might just be indicator light";
CM_ SG_ 773 PASS_AIRBAG_OFF "Might just be indicator light";
CM_ SG_ 780 CRUISE_SPEED "255 = no speed";
CM_ SG_ 780 PCM_SPEED "Used by Nidec";
CM_ SG_ 780 PCM_GAS "Used by Nidec";
CM_ SG_ 804 CRUISE_SPEED_PCM "255 = no speed";

CM_ "Imported file _bosch_2018.dbc starts here";
CM_ SG_ 450 EPB_STATE "3: On, 2: Disengaging, 1: Engaging, 0: Off";
CM_ SG_ 576 LINE_DISTANCE_VISIBLE "Length of line visible, undecoded";
CM_ SG_ 577 LINE_FAR_EDGE_POSITION "Appears to be a measure of line thickness, indicates location of the portion of the line furthest from the car, undecoded";
CM_ SG_ 577 LINE_PARAMETER "Unclear if this is low quality line curvature rate or if this is something else, but it is correlated with line curvature, undecoded";
CM_ SG_ 577 LINE_DASHED "1 = line is dashed";
CM_ SG_ 577 LINE_SOLID "1 = line is solid";

CM_ "Imported file _bosch_adas_2018.dbc starts here";
CM_ SG_ 479 CONTROL_ON "Set to 5 when car is being controlled";
CM_ SG_ 479 AEB_STATUS "set for the duration of AEB event";
CM_ SG_ 479 AEB_BRAKING "set when braking is commanded during AEB event";
CM_ SG_ 479 AEB_PREPARE "set 1s before AEB";
CM_ SG_ 829 BEEP "beeps are pleasant, chimes are for warnngs etc...";

CM_ "Imported file _steering_sensors_b.dbc starts here";
CM_ "acura_rdx_2020_can.dbc starts here";

VAL_ 513 STATE 5 "FAULT_TIMEOUT" 4 "FAULT_STARTUP" 3 "FAULT_SCE" 2 "FAULT_SEND" 1 "FAULT_BAD_CHECKSUM" 0 "NO_FAULT" ;

VAL_ 780 CRUISE_SPEED 255 "no_speed" 252 "stopped";
VAL_ 780 HUD_LEAD 3 "acc_off" 2 "solid_car" 1 "dashed_car" 0 "no_car";
VAL_ 884 DASHBOARD_ALERT 0 "none" 51 "acc_problem" 55 "cmbs_problem" 75 "key_not_detected" 79 "fasten_seatbelt" 111 "lkas_problem" 131 "brake_system_problem" 132 "brake_hold_problem" 139 "tbd" 161 "door_open";
VAL_ 891 WIPERS 4 "High" 2 "Low" 0 "Off";

VAL_ 506 FCW 3 "fcw" 2 "fcw" 1 "fcw" 0 "no_fcw";
VAL_ 506 CHIME 4 "double_chime" 3 "single_chime" 2 "continuous_chime" 1 "repeating_chime" 0 "no_chime";
VAL_ 506 AEB_STATUS 3 "aeb_prepare" 2 "aeb_ready" 1 "aeb_braking" 0 "no_aeb";
VAL_ 829 BEEP 3 "single_beep" 2 "triple_beep" 1 "repeated_beep" 0 "no_beep";

VAL_ 399 STEER_STATUS 6 "tmp_fault" 5 "fault_1" 4 "no_torque_alert_2" 3 "low_speed_lockout" 2 "no_torque_alert_1" 0 "normal" ;
VAL_ 401 GEAR_SHIFTER 32 "L" 16 "S" 8 "D" 4 "N" 2 "R" 1 "P" ;
VAL_ 401 GEAR 7 "L" 10 "S" 4 "D" 3 "N" 2 "R" 1 "P" ;
VAL_ 422 CRUISE_BUTTONS 7 "tbd" 6 "tbd" 5 "tbd" 4 "accel_res" 3 "decel_set" 2 "cancel" 1 "main" 0 "none" ;
VAL_ 422 LIGHTS_SETTING 3 "high_beam" 2 "low_beam" 1 "position" 0 "no_lights" ;
